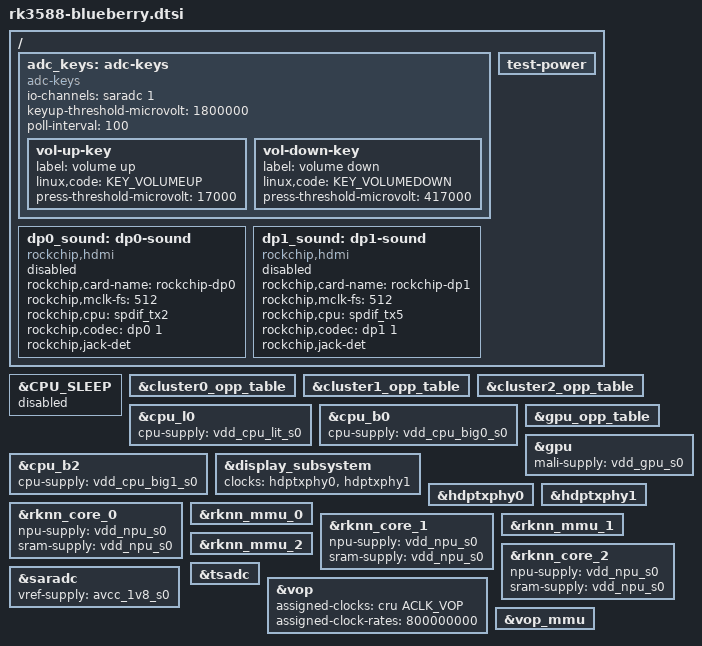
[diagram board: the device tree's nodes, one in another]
// SPDX-License-Identifier: (GPL-2.0+ OR MIT)
/*
 * Copyright (c) 2026 Valentin Liu <valentinliu@icloud.com>
 */

#include <dt-bindings/gpio/gpio.h>
#include <dt-bindings/pwm/pwm.h>
#include <dt-bindings/leds/common.h>
#include <dt-bindings/input/input.h>
#include <dt-bindings/pinctrl/rockchip.h>
#include <dt-bindings/usb/pd.h>
#include "rk3588.dtsi"

/ {
	adc_keys: adc-keys {
		compatible = "adc-keys";
		io-channels = <&saradc 1>;
		io-channel-names = "buttons";
		keyup-threshold-microvolt = <1800000>;
		poll-interval = <100>;

		vol-up-key {
			label = "volume up";
			linux,code = <KEY_VOLUMEUP>;
			press-threshold-microvolt = <17000>;
		};

		vol-down-key {
			label = "volume down";
			linux,code = <KEY_VOLUMEDOWN>;
			press-threshold-microvolt = <417000>;
		};

	};

	dp0_sound: dp0-sound {
		status = "disabled";
		compatible = "rockchip,hdmi";
		rockchip,card-name = "rockchip-dp0";
		rockchip,mclk-fs = <512>;
		rockchip,cpu = <&spdif_tx2>;
		rockchip,codec = <&dp0 1>;
		rockchip,jack-det;
	};

	dp1_sound: dp1-sound {
		status = "disabled";
		compatible = "rockchip,hdmi";
		rockchip,card-name = "rockchip-dp1";
		rockchip,mclk-fs = <512>;
		rockchip,cpu = <&spdif_tx5>;
		rockchip,codec = <&dp1 1>;
		rockchip,jack-det;
	};

	test-power {
		status = "okay";
	};
};


/* CPU section */
&CPU_SLEEP {
	status = "disabled";
};

&cluster0_opp_table {
	/delete-node/ opp-600000000;
	/delete-node/ opp-1008000000;
};

&cluster1_opp_table {
	/delete-node/ opp-600000000;
	/delete-node/ opp-1008000000;
};

&cluster2_opp_table {
	/delete-node/ opp-600000000;
	/delete-node/ opp-1008000000;
};

&cpu_l0 {
	cpu-supply = <&vdd_cpu_lit_s0>;
};

&cpu_b0 {
	cpu-supply = <&vdd_cpu_big0_s0>;
};

&cpu_b2 {
	cpu-supply = <&vdd_cpu_big1_s0>;
};


/* Display Subsystem section */
&display_subsystem {
	clocks = <&hdptxphy0>, <&hdptxphy1>;
	// clock-names = "hdmi0_phy_pll", "hdmi1_phy_pll";
	status = "okay";
};


/* GPU section */
&gpu_opp_table {
	/delete-node/ opp-500000000;
	/delete-node/ opp-1000000000;
};

&gpu {
	mali-supply = <&vdd_gpu_s0>;
	status = "okay";
};


/* HDMI PHY section */
&hdptxphy0 {
	status = "okay";
};

&hdptxphy1 {
	status = "okay";
};


/* Rockchip NPU section */
&rknn_core_0 {
	npu-supply = <&vdd_npu_s0>;
	sram-supply = <&vdd_npu_s0>;
	status = "okay";
};

&rknn_mmu_0 {
	status = "okay";
};

&rknn_core_1 {
	npu-supply = <&vdd_npu_s0>;
	sram-supply = <&vdd_npu_s0>;
	status = "okay";
};

&rknn_mmu_1 {
	status = "okay";
};

&rknn_core_2 {
	npu-supply = <&vdd_npu_s0>;
	sram-supply = <&vdd_npu_s0>;
	status = "okay";
};

&rknn_mmu_2 {
	status = "okay";
};


/* ADC section */
&saradc {
	status = "okay";
	vref-supply = <&avcc_1v8_s0>;
};

&tsadc {
	status = "okay";
};


/* Rockchip Video Output Processor section */
&vop {
	assigned-clocks = <&cru ACLK_VOP>;
	assigned-clock-rates = <800000000>;
	status = "okay";
};

&vop_mmu {
	status = "okay";
};
